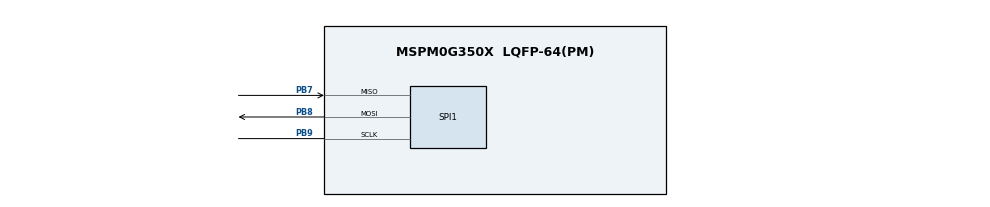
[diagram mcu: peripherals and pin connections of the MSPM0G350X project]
/**
 * @cliArgs --device "MSPM0G350X" --package "LQFP-64(PM)" --part "Default" --product "mspm0_sdk@2.00.01.00"
 * @versions {"tool":"1.20.0+3587"}
 */

/**
 * Import the modules used in this configuration.
 */
const SPI    = scripting.addModule("/ti/driverlib/SPI", {}, false);
const SPI1   = SPI.addInstance();
const SYSCTL = scripting.addModule("/ti/driverlib/SYSCTL");

/**
 * Write custom configuration values to the imported modules.
 */
SPI1.$name                              = "SPI1";
SPI1.targetBitRate                      = 800000;
SPI1.frameFormat                        = "MOTO3";
SPI1.peripheral.$assign                 = "SPI1";
SPI1.peripheral.sclkPin.$assign         = "PB9";
SPI1.peripheral.mosiPin.$assign         = "PB8";
SPI1.peripheral.misoPin.$assign         = "PB7";
SPI1.sclkPinConfig.$name                = "ti_driverlib_gpio_GPIOPinGeneric0";
SPI1.sclkPinConfig.direction            = scripting.forceWrite("OUTPUT");
SPI1.sclkPinConfig.onlyInternalResistor = scripting.forceWrite(false);
SPI1.sclkPinConfig.passedPeripheralType = scripting.forceWrite("Digital");
SPI1.mosiPinConfig.$name                = "ti_driverlib_gpio_GPIOPinGeneric1";
SPI1.mosiPinConfig.direction            = scripting.forceWrite("OUTPUT");
SPI1.mosiPinConfig.hideOutputInversion  = scripting.forceWrite(false);
SPI1.mosiPinConfig.onlyInternalResistor = scripting.forceWrite(false);
SPI1.mosiPinConfig.passedPeripheralType = scripting.forceWrite("Digital");
SPI1.misoPinConfig.$name                = "ti_driverlib_gpio_GPIOPinGeneric2";
SPI1.misoPinConfig.onlyInternalResistor = scripting.forceWrite(false);
SPI1.misoPinConfig.passedPeripheralType = scripting.forceWrite("Digital");

const Board = scripting.addModule("/ti/driverlib/Board", {}, false);

SYSCTL.forceDefaultClkConfig = true;

/**
 * Pinmux solution for unlocked pins/peripherals. This ensures that minor changes to the automatic solver in a future
 * version of the tool will not impact the pinmux you originally saw.  These lines can be completely deleted in order to
 * re-solve from scratch.
 */
Board.peripheral.$suggestSolution          = "DEBUGSS";
Board.peripheral.swclkPin.$suggestSolution = "PA20";
Board.peripheral.swdioPin.$suggestSolution = "PA19";
SYSCTL.peripheral.$suggestSolution         = "SYSCTL";
